VERSION ""

NS_ :

BS_:

BU_: VCM INVmc EShift HVAC TCU OBCpd HVBAT

BO_ 3221225472 VECTOR__INDEPENDENT_SIG_MSG: 0 Vector__XXX
 SG_ Unknown_55B_5 m3 : 40|8@1+ (1,0) [0|0] "" Vector__XXX
 SG_ StopChargeMaybe : 52|4@1+ (1,0) [0|0] "" Vector__XXX

BO_ 1468 x5BC: 8 HVBAT
 SG_ GIDs : 7|10@0+ (1,0) [0|500] "gids" Vector__XXX
 SG_ Mux M : 32|4@1+ (1,0) [0|0] "" Vector__XXX
 SG_ BatteryTemperature : 24|8@1+ (1,0) [0|0] "dC" Vector__XXX
 SG_ BatteryChargeGaugeOffset : 36|4@1+ (1,0) [0|15] "" Vector__XXX
 SG_ ChargeBars m8 : 20|4@1+ (1,0) [0|15] "-" Vector__XXX
 SG_ CapacityBars m9 : 20|4@1+ (1,0) [0|15] "" Vector__XXX

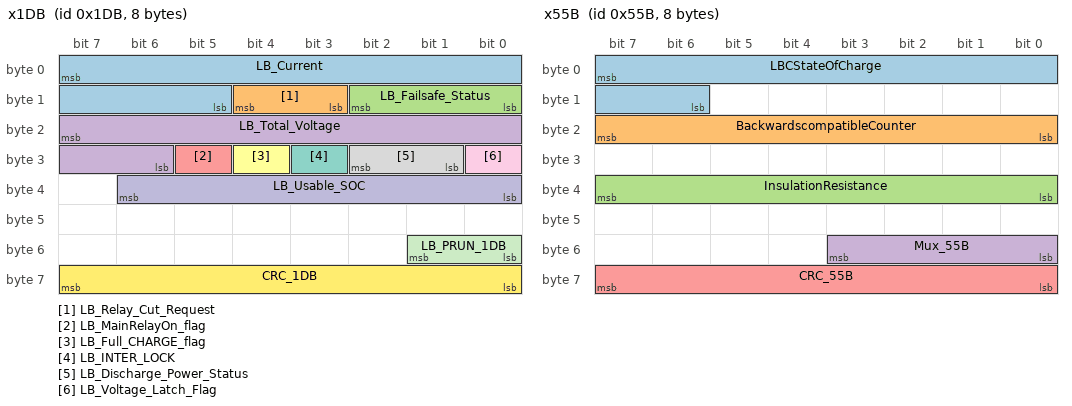
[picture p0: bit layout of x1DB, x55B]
BO_ 475 x1DB: 8 HVBAT
 SG_ LB_Current : 7|11@0+ (0.5,0) [-400|200] "A" Vector__XXX
 SG_ LB_Relay_Cut_Request : 11|2@1+ (1,0) [0|0] "MODEMASK" Vector__XXX
 SG_ LB_Failsafe_Status : 8|3@1+ (1,0) [0|0] "MODEMASK" Vector__XXX
 SG_ LB_Total_Voltage : 23|10@0+ (0.5,0) [0|450] "V" Vector__XXX
 SG_ LB_MainRelayOn_flag : 29|1@1+ (1,0) [0|0] "MODEMASK" Vector__XXX
 SG_ LB_Full_CHARGE_flag : 28|1@1+ (1,0) [0|0] "" Vector__XXX
 SG_ LB_INTER_LOCK : 27|1@1+ (1,0) [0|0] "MODEMASK" Vector__XXX
 SG_ LB_Discharge_Power_Status : 25|2@1+ (1,0) [0|0] "MODEMASK" Vector__XXX
 SG_ LB_Voltage_Latch_Flag : 24|1@1+ (1,0) [0|0] "MODEMASK" Vector__XXX
 SG_ LB_Usable_SOC : 32|7@1+ (1,0) [0|0] "" Vector__XXX
 SG_ LB_PRUN_1DB : 48|2@1+ (1,0) [0|0] "" Vector__XXX
 SG_ CRC_1DB : 56|8@1+ (1,0) [0|0] "CRC" Vector__XXX

BO_ 1371 x55B: 8 HVBAT
 SG_ LBCStateOfCharge : 7|10@0+ (1,0) [0|0] "%+1" Vector__XXX
 SG_ BackwardscompatibleCounter : 16|8@1+ (1,0) [85|170] "" Vector__XXX
 SG_ InsulationResistance : 32|8@1+ (1,0) [0|255] "" Vector__XXX
 SG_ Mux_55B M : 48|4@1+ (1,0) [0|0] "" Vector__XXX
 SG_ CRC_55B : 56|8@1+ (1,0) [0|0] "" Vector__XXX

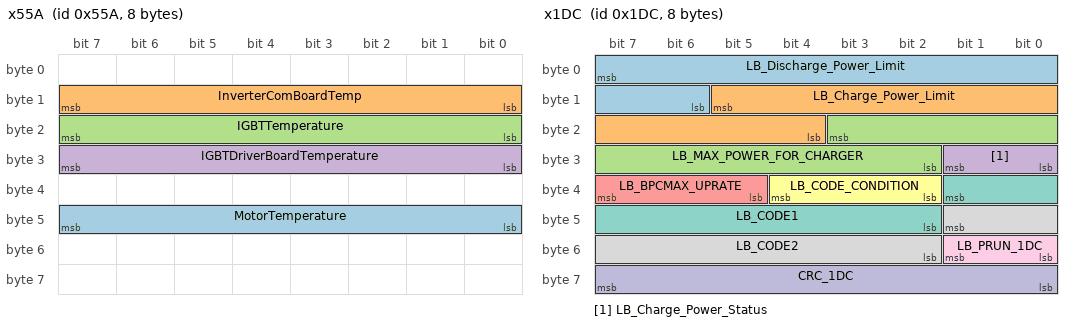
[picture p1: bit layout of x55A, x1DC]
BO_ 1370 x55A: 8 INVmc
 SG_ MotorTemperature : 40|8@1+ (1,0) [0|255] "dC*2" Vector__XXX
 SG_ InverterComBoardTemp : 8|8@1+ (1,0) [0|255] "dC*2" Vector__XXX
 SG_ IGBTTemperature : 16|8@1+ (1,0) [0|255] "dC*2" Vector__XXX
 SG_ IGBTDriverBoardTemperature : 24|8@1+ (1,0) [0|255] "dC*2" Vector__XXX

BO_ 476 x1DC: 8 HVBAT
 SG_ LB_Discharge_Power_Limit : 7|10@0+ (0.25,0) [0|254] "kW" Vector__XXX
 SG_ LB_Charge_Power_Limit : 13|10@0+ (0.25,0) [0|254] "kW" Vector__XXX
 SG_ LB_MAX_POWER_FOR_CHARGER : 19|10@0+ (0.1,-10) [-10|90] "kW" Vector__XXX
 SG_ LB_Charge_Power_Status : 24|2@1+ (1,0) [0|0] "MODEMASK" Vector__XXX
 SG_ LB_BPCMAX_UPRATE : 37|3@1+ (1,0) [0|0] "MODEMASK" Vector__XXX
 SG_ LB_CODE_CONDITION : 34|3@1+ (1,0) [0|0] "" Vector__XXX
 SG_ LB_CODE1 : 33|8@0+ (1,0) [0|0] "" Vector__XXX
 SG_ LB_CODE2 : 41|8@0+ (1,0) [0|0] "" Vector__XXX
 SG_ LB_PRUN_1DC : 48|2@1+ (1,0) [0|3] "" Vector__XXX
 SG_ CRC_1DC : 56|8@1+ (1,0) [0|0] "CRC" Vector__XXX

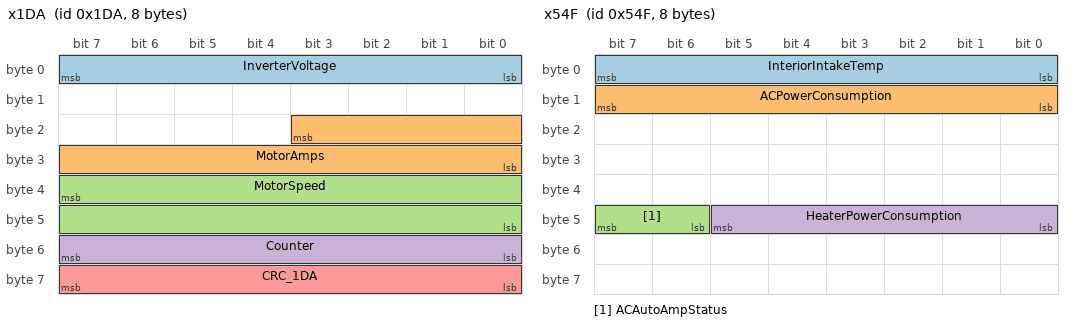
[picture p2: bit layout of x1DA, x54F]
BO_ 474 x1DA: 8 INVmc
 SG_ InverterVoltage : 0|8@1+ (1,0) [0|200] "V*2" Vector__XXX
 SG_ MotorAmps : 19|12@0+ (1,0) [0|250] "A" Vector__XXX
 SG_ MotorSpeed : 39|16@0+ (1,0) [0|24000] "rpm/2" Vector__XXX
 SG_ Counter : 48|8@1+ (1,0) [0|3] "" Vector__XXX
 SG_ CRC_1DA : 56|8@1+ (1,0) [0|0] "CRC" Vector__XXX

BO_ 1465 x5B9: 7 VCM
 SG_ ActiveFuelBars : 3|5@1+ (1,0) [0|12] "-" Vector__XXX
 SG_ ChargeMinutesRemaining : 2|11@0+ (1,0) [0|2047] "minutes" Vector__XXX

BO_ 1359 x54F: 8 HVAC
 SG_ InteriorIntakeTemp : 0|8@1+ (1,0) [0|0] "F or 0.5C" Vector__XXX
 SG_ ACPowerConsumption : 8|8@1+ (1,0) [0|0] "50W/bit?" Vector__XXX
 SG_ ACAutoAmpStatus : 46|2@1+ (1,0) [0|0] "-" Vector__XXX
 SG_ HeaterPowerConsumption : 40|6@1+ (1,0) [0|0] "300W/bit?" Vector__XXX

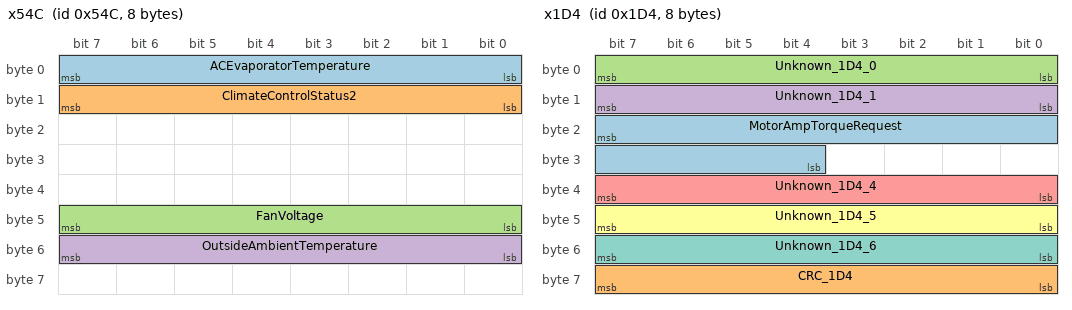
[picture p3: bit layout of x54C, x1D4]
BO_ 1356 x54C: 8 HVAC
 SG_ ACEvaporatorTemperature : 0|8@1+ (1,0) [0|0] "0.25C/bit?" Vector__XXX
 SG_ ClimateControlStatus2 : 8|8@1+ (1,0) [0|0] "-" Vector__XXX
 SG_ FanVoltage : 40|8@1+ (1,0) [0|0] "0.05 V/bit" Vector__XXX
 SG_ OutsideAmbientTemperature : 48|8@1+ (1,0) [0|0] "F/C" Vector__XXX

BO_ 282 x11A: 8 VCM
 SG_ JoystickGearPosition : 4|4@1+ (1,0) [0|0] "-" Vector__XXX
 SG_ CarOnOffStatus : 8|8@1+ (1,0) [0|0] "-" Vector__XXX
 SG_ Mulitplexor M : 48|8@1+ (1,0) [0|0] "" Vector__XXX
 SG_ StartupDataUnknown0 m0 : 56|8@1+ (1,0) [0|0] "" Vector__XXX
 SG_ StartupDataUnknown1 m1 : 56|8@1+ (1,0) [0|0] "" Vector__XXX
 SG_ StartupDataUnknown2 m2 : 56|8@1+ (1,0) [0|0] "" Vector__XXX
 SG_ StartupDataUnknown3 m3 : 56|8@1+ (1,0) [0|0] "" Vector__XXX
 SG_ SteeringWheelButton : 16|8@1+ (1,0) [0|0] "" Vector__XXX
 SG_ HeartbeatVCM : 24|8@1+ (1,0) [85|170] "" Vector__XXX
 SG_ Unknown_11A_4_0 m0 : 32|8@1+ (1,0) [0|0] "" Vector__XXX
 SG_ Unknown_11A_4_1 m1 : 32|8@1+ (1,0) [0|0] "" Vector__XXX
 SG_ Unknown_11A_4_2 m2 : 32|8@1+ (1,0) [0|0] "" Vector__XXX
 SG_ Unknown_11A_4_3 m3 : 32|8@1+ (1,0) [0|0] "" Vector__XXX

BO_ 468 x1D4: 8 Vector__XXX
 SG_ MotorAmpTorqueRequest : 23|12@0+ (1,0) [0|0] "" Vector__XXX
 SG_ CRC_1D4 : 56|8@1+ (1,0) [0|0] "CRC" Vector__XXX
 SG_ Unknown_1D4_0 : 0|8@1+ (1,0) [0|0] "" Vector__XXX
 SG_ Unknown_1D4_1 : 8|8@1+ (1,0) [0|0] "" Vector__XXX
 SG_ Unknown_1D4_4 : 32|8@1+ (1,0) [0|0] "" Vector__XXX
 SG_ Unknown_1D4_5 : 40|8@1+ (1,0) [0|0] "" Vector__XXX
 SG_ Unknown_1D4_6 : 48|8@1+ (1,0) [0|0] "" Vector__XXX

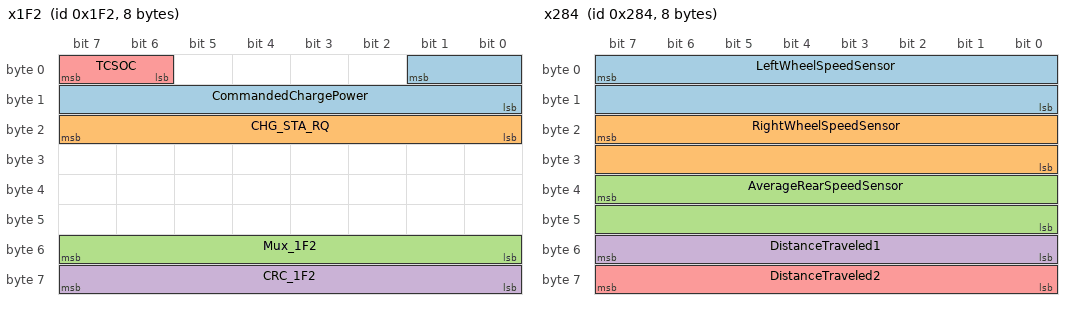
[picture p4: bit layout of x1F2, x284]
BO_ 498 x1F2: 8 VCM
 SG_ CommandedChargePower : 1|10@0+ (1,0) [0|0] "" Vector__XXX
 SG_ CHG_STA_RQ : 16|8@1+ (1,0) [0|0] "" Vector__XXX
 SG_ Mux_1F2 M : 48|8@1+ (1,0) [0|3] "" Vector__XXX
 SG_ CRC_1F2 : 56|8@1+ (1,0) [0|0] "" Vector__XXX
 SG_ TCSOC : 6|2@1+ (1,0) [0|0] "" Vector__XXX

BO_ 644 x284: 8 VCM
 SG_ LeftWheelSpeedSensor : 7|16@0+ (1,0) [0|65535] "pulses" Vector__XXX
 SG_ RightWheelSpeedSensor : 23|16@0+ (1,0) [0|65535] "pulses" Vector__XXX
 SG_ AverageRearSpeedSensor : 39|16@0+ (1,0) [0|65535] "pulses" Vector__XXX
 SG_ DistanceTraveled1 : 48|8@1+ (1,0) [0|255] "" Vector__XXX
 SG_ DistanceTraveled2 : 56|8@1+ (1,0) [0|255] "" Vector__XXX

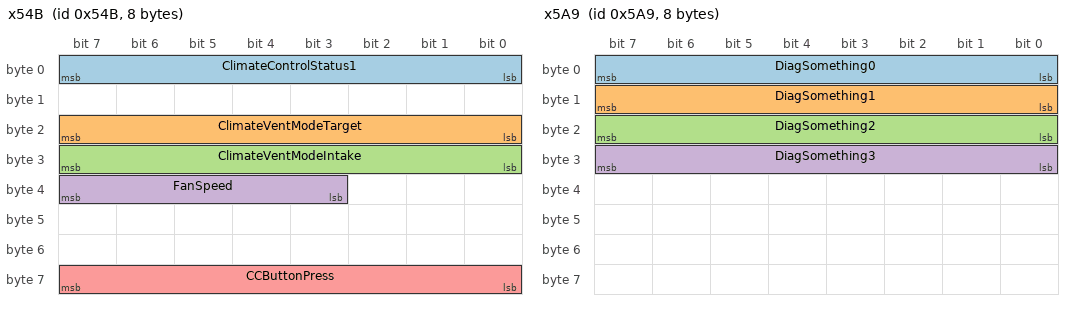
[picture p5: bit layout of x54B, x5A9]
BO_ 1355 x54B: 8 HVAC
 SG_ ClimateControlStatus1 : 0|8@1+ (1,0) [0|0] "status" Vector__XXX
 SG_ ClimateVentModeTarget : 16|8@1+ (1,0) [0|0] "status" Vector__XXX
 SG_ ClimateVentModeIntake : 24|8@1+ (1,0) [0|0] "status" Vector__XXX
 SG_ FanSpeed : 35|5@1+ (1,0) [1|7] "speed" Vector__XXX
 SG_ CCButtonPress : 56|8@1+ (1,0) [0|0] "0/1" Vector__XXX

BO_ 1449 x5A9: 8 VCM
 SG_ DiagSomething0 : 0|8@1+ (1,0) [0|0] "" Vector__XXX
 SG_ DiagSomething1 : 8|8@1+ (1,0) [0|0] "" Vector__XXX
 SG_ DiagSomething2 : 16|8@1+ (1,0) [0|0] "" Vector__XXX
 SG_ DiagSomething3 : 24|8@1+ (1,0) [0|0] "" Vector__XXX

BO_ 1472 x5C0: 8 HVBAT
 SG_ Mux5C0 M : 0|8@1+ (1,0) [0|0] "" Vector__XXX
 SG_ ClusterTemperature2 m64 : 16|8@1+ (1,0) [0|0] "dC" Vector__XXX
 SG_ DisOrChargeTimeCounter : 24|8@1- (1,0) [0|255] "Counter" Vector__XXX
 SG_ Unknown5C0_byte4 : 32|8@1+ (1,0) [0|0] "" Vector__XXX
 SG_ Unknown5C0_byte5_mux40 m64 : 40|8@1+ (1,0) [0|0] "" Vector__XXX
 SG_ Unknown5C0_byte5_mux80 m128 : 40|8@1+ (1,0) [0|0] "" Vector__XXX
 SG_ Unknown5C0_byte5_muxC0 m192 : 48|8@1+ (1,0) [0|0] "" Vector__XXX

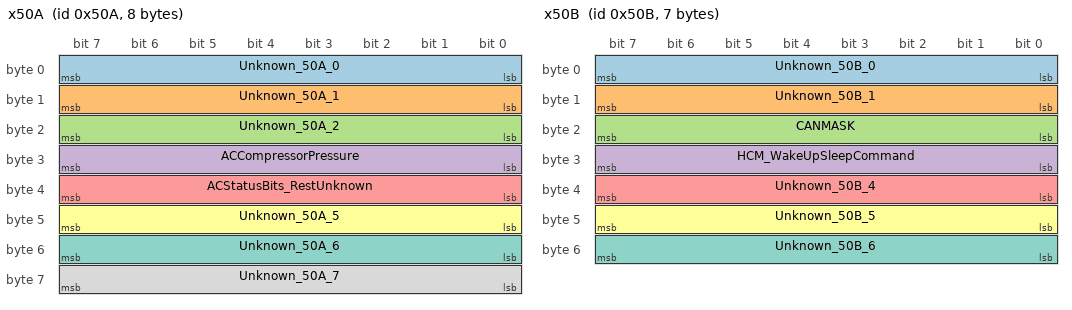
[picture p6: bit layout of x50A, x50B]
BO_ 1290 x50A: 8 VCM
 SG_ Unknown_50A_0 : 0|8@1+ (1,0) [0|0] "" Vector__XXX
 SG_ Unknown_50A_1 : 8|8@1+ (1,0) [0|0] "" Vector__XXX
 SG_ Unknown_50A_2 : 16|8@1+ (1,0) [0|0] "" Vector__XXX
 SG_ ACCompressorPressure : 24|8@1+ (1,0) [0|0] "" Vector__XXX
 SG_ ACStatusBits_RestUnknown : 32|8@1+ (1,0) [0|0] "" Vector__XXX
 SG_ Unknown_50A_5 : 40|8@1+ (1,0) [0|0] "" Vector__XXX
 SG_ Unknown_50A_6 : 48|8@1+ (1,0) [0|0] "" Vector__XXX
 SG_ Unknown_50A_7 : 56|8@1+ (1,0) [0|0] "" Vector__XXX

BO_ 1291 x50B: 7 VCM
 SG_ Unknown_50B_0 : 0|8@1+ (1,0) [0|0] "" Vector__XXX
 SG_ Unknown_50B_1 : 8|8@1+ (1,0) [0|0] "" Vector__XXX
 SG_ CANMASK : 16|8@1+ (1,0) [0|0] "" Vector__XXX
 SG_ HCM_WakeUpSleepCommand : 24|8@1+ (1,0) [0|0] "" Vector__XXX
 SG_ Unknown_50B_4 : 32|8@1+ (1,0) [0|0] "" Vector__XXX
 SG_ Unknown_50B_5 : 40|8@1+ (1,0) [0|0] "" Vector__XXX
 SG_ Unknown_50B_6 : 48|8@1+ (1,0) [0|0] "" Vector__XXX

BO_ 1292 x50C: 6 Vector__XXX
 SG_ Unknown_50C_0 : 0|8@1+ (1,0) [0|0] "" Vector__XXX
 SG_ Unknown_50C_1 : 8|8@1+ (1,0) [0|0] "" Vector__XXX
 SG_ Unknown_50C_2 : 16|8@1+ (1,0) [0|0] "" Vector__XXX
 SG_ Mux_50C M : 24|8@1+ (1,0) [0|0] "" Vector__XXX
 SG_ ALU_Question : 32|8@1+ (1,0) [0|0] "" Vector__XXX
 SG_ Unknown_50C_5_0 m0 : 40|8@1+ (1,0) [0|0] "" Vector__XXX
 SG_ Unknown_50C_5_1 m1 : 40|8@1+ (1,0) [0|0] "" Vector__XXX
 SG_ Unknown_50C_5_2 m2 : 40|8@1+ (1,0) [0|0] "" Vector__XXX
 SG_ Unknown_50C_5_3 m3 : 40|8@1+ (1,0) [0|0] "" Vector__XXX

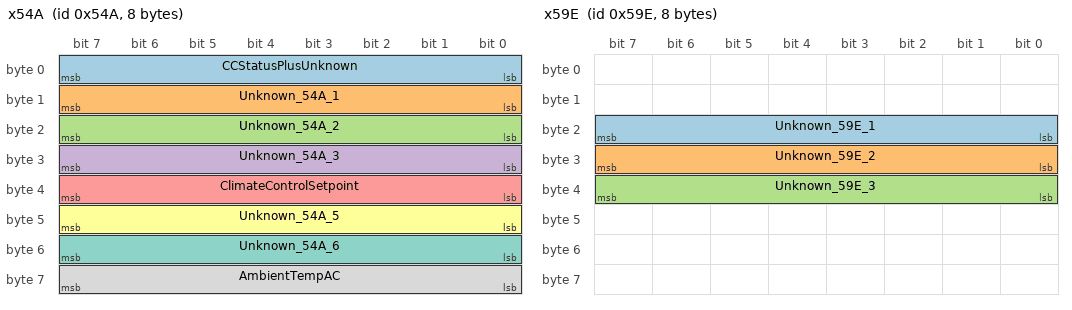
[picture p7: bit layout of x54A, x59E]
BO_ 1354 x54A: 8 HVAC
 SG_ CCStatusPlusUnknown : 0|8@1+ (1,0) [0|0] "" Vector__XXX
 SG_ Unknown_54A_1 : 8|8@1+ (1,0) [0|0] "" Vector__XXX
 SG_ Unknown_54A_2 : 16|8@1+ (1,0) [0|0] "" Vector__XXX
 SG_ Unknown_54A_3 : 24|8@1+ (1,0) [0|0] "" Vector__XXX
 SG_ ClimateControlSetpoint : 32|8@1+ (1,0) [0|0] "" Vector__XXX
 SG_ Unknown_54A_5 : 40|8@1+ (1,0) [0|0] "" Vector__XXX
 SG_ Unknown_54A_6 : 48|8@1+ (1,0) [0|0] "" Vector__XXX
 SG_ AmbientTempAC : 56|8@1+ (1,0) [0|0] "" Vector__XXX

BO_ 1118 x45E: 1 Vector__XXX

BO_ 1438 x59E: 8 Vector__XXX
 SG_ Unknown_59E_1 : 16|8@1+ (1,0) [0|0] "" Vector__XXX
 SG_ Unknown_59E_2 : 24|8@1+ (1,0) [0|0] "" Vector__XXX
 SG_ Unknown_59E_3 : 32|8@1+ (1,0) [0|0] "" Vector__XXX

BO_ 1153 x481: 2 Vector__XXX
 SG_ Unknown_481_1 : 0|8@1+ (1,0) [0|0] "" Vector__XXX
 SG_ Unknown_481_2 : 8|8@1+ (1,0) [0|0] "" Vector__XXX

BO_ 912 x390: 8 Vector__XXX
 SG_ Unknown_390_7 : 56|8@1+ (1,0) [0|0] "" Vector__XXX

BO_ 915 x393: 8 Vector__XXX
 SG_ Unknown_393_8 : 56|8@1+ (1,0) [0|0] "" Vector__XXX

BO_ 1539 x603: 8 Vector__XXX

CM_ BU_ VCM "Vehicle Control Module";
CM_ BU_ INVmc "Inverter Motor Controller";
CM_ BO_ 1468 "Lithium Battery Controller";
CM_ SG_ 1468 GIDs "0-281 for 24kWh  0-363 for 30kWh 0-498 for 40kWh
1 LSB = 65-85WH";
CM_ SG_ 1468 Mux "Mux field for capacity bars and charge bars 
8/9 on 2013-2017, 14/15 on 2018-2019";
CM_ SG_ 1468 BatteryTemperature "Should be average of the 3/4 sensors inside the battery pack (0x50 = 80DEC = 8.0*C)";
CM_ SG_ 1468 BatteryChargeGaugeOffset "Somehow effects the charge gauge, lower numbers mean more bars";
CM_ SG_ 1468 ChargeBars "Range 0-15 (Below data from test at 0%SOC, writing values to bus)
15 = 12 chargebars
14 = 12 chargebars
13 = 11 chargebars
12 = 10 chargebars
11 = 9 chargebars
10 = 8 chargebars !
9 = 8 chargebars !
8 = 7 chargebars
7 = 6 chargebars
6 = 5 chargebars
5 = 4 chargebars !
4 = 4 chargebars !
3 = 3 chargebars
2 = 2 chargebars
1 = 1 chargebars
0 = 0 chargebars";
CM_ SG_ 1468 CapacityBars "0-15 
15 = 12 capacitybars
14 = 12 capacitybars
13 = 11 capacitybars
12 = 10 capacitybars
11 = 9 capacitybars
10 = 8 capacitybars !
9 = 8 capacitybars !
8 = 7 capacitybars
7 = 6 capacitybars
6 = 5 capacitybars
5 = 4 capacitybars !
4 = 4 capacitybars !
3 = 3 capacitybars
2 = 2 capacitybars
1 = 1 capacitybars
0 = 0 capacitybars
";
CM_ BO_ 475 "Lithium Battery Controller (10ms)";
CM_ SG_ 475 LB_Current "BatteryCurrentSignal , 2s comp, 1lSB = 0.5A";
CM_ SG_ 475 LB_Relay_Cut_Request "00 = No-Request 01 = Main Relay OFF Request 10 = Main Relay OFF Request 11 = Main Relay OFF Request";
CM_ SG_ 475 LB_Failsafe_Status "Request Stop charging. This is the command to request stop charging
frame.data[1] = (frame.data[1] & 0xE0) | 2;

000b = normal start Request 001b = Normal Stop Request 010b = Charging Mode Stop Request 011b = Charging Mode Stop Request & Normal Stop Request 100b = Caution Lamp Request 101b = Caution Lamp Request & Normal Stop Request 110b = Caution Lamp Request & Charging Mode Stop Request 111b = Caution Lamp Request & Charging Mode Stop Request & Normal Stop Request";
CM_ SG_ 475 LB_Total_Voltage "0.5V/bit
";
CM_ SG_ 475 LB_MainRelayOn_flag "0h = No-Permission 1h = Main Relay On Permission";
CM_ SG_ 475 LB_INTER_LOCK "0h = Not Inter Lock connected 1h = Inter Lock connected";
CM_ SG_ 475 LB_Discharge_Power_Status "00b = Reserved 01b = Normal limit POUT 10b = High rate limit POUT 11b = Immediate limit POUT";
CM_ SG_ 475 LB_Voltage_Latch_Flag "0->1:Cell Volatage Latch
1->0:Cell Volatage Latch";
CM_ SG_ 475 LB_Usable_SOC "Contains SOC for dash (% without decimals) [Needs to be copied to this location when doing 40/62kWh swaps into AZE0]";
CM_ SG_ 475 LB_PRUN_1DB "MPR1DB";
CM_ SG_ 475 CRC_1DB "CRC";
CM_ BO_ 1371 "Lithium Battery Controller";
CM_ SG_ 1371 LBCStateOfCharge "Does not affect cluster or VCM at all";
CM_ SG_ 1371 BackwardscompatibleCounter "55,AA (alternates every 500ms) Works as a mux

This message is repeated 5x, to offer backwardscompability to 2011/2013 models. The message on these cars are run at 500ms.";
CM_ SG_ 1371 Mux_55B "00,01,02,03";
CM_ BO_ 1370 "Inverter";
CM_ SG_ 1370 MotorTemperature "Stays at 0 on 2015 Leaf?";
CM_ SG_ 1370 InverterComBoardTemp "Inverter communications board temp";
CM_ SG_ 1370 IGBTDriverBoardTemperature "Temperature only active during drive (IGBT driver board?)";
CM_ BO_ 476 "Lithium Battery Controller (10ms)";
CM_ SG_ 476 LB_Discharge_Power_Limit "Max available power that can be pulled from battery";
CM_ SG_ 476 LB_Charge_Power_Limit "Max power that battery can be charged with";
CM_ SG_ 476 LB_Charge_Power_Status "00b = Reserved 01b = Normal limit PIN 10b = High rate limit PIN 11b = Immediate limit PIN";
CM_ SG_ 476 LB_BPCMAX_UPRATE "000b : BPC MAX Uprate Level 1 001b : BPC MAX Uprate Level 2 010b : BPC MAX Uprate Level 3 011b : BPC MAX Uprate Level 4 100b : BPC MAX Uprate Level 5 101b : BPC MAX Uprate Level 6 110b : BPC MAX Uprate Level 7 111b : BPC MAX Uprate Level 8";
CM_ SG_ 476 CRC_1DC "CRC";
CM_ BO_ 474 "Inverter";
CM_ SG_ 474 InverterVoltage "2V/bit
01..b9 Follows BVS(BatteryVoltageSignal) until near end of drive (turtle?) or end of charging ";
CM_ SG_ 474 MotorAmps "Something not right here.

Motor Amps * Motor Volts is really close to pack watts*40 Maybe 1lsb=0.5A";
CM_ SG_ 474 MotorSpeed "16 bits; 1 LSB = 0.5rpm? Stays at zero when applying torque with brake on so not likely volts.";
CM_ SG_ 474 Counter "Safety counter / Or mux?";
CM_ SG_ 474 CRC_1DA "CRC";
CM_ BO_ 1465 "Vehicle Control Module";
CM_ SG_ 1465 ActiveFuelBars "From VCM->Cluster";
CM_ SG_ 1465 ChargeMinutesRemaining "Minutes from 3kW charging estimate on dash.

Example:
0x09 FE
0000 1001 1111 1110
001 1111 1110 = 510min";
CM_ BO_ 1359 "AC Auto Amp";
CM_ SG_ 1359 InteriorIntakeTemp "Appears to be interior intake temp
(2013: sometimes is <0x20 when the temp is definitely higher)

My testing during 8*C according to dash, warm interior
0x34 = 52 DEC
52F = 11C?
52/2= 26C?";
CM_ SG_ 1359 ACPowerConsumption "Rises to a steady value with ac on.  Off immediately with ac off.  No change with heater on";
CM_ SG_ 1359 ACAutoAmpStatus "location?";
CM_ SG_ 1359 HeaterPowerConsumption "Goes up slowly with heater on; no change with ac on";
CM_ BO_ 1356 "AC Auto Amp";
CM_ SG_ 1356 ACEvaporatorTemperature "drops with ac on (after short lag).  No change with heater on";
CM_ SG_ 1356 ClimateControlStatus2 "66 CC on, ff CC off";
CM_ SG_ 1356 FanVoltage "Commanded fan speed is proportional to Voltage";
CM_ SG_ 1356 OutsideAmbientTemperature "0x92=90F;0x86=79F (90F & 79F read from dash)";
CM_ BO_ 282 "Vehicle Control Module 2013+ (Shift controller module for 2011-2012)";
CM_ SG_ 282 JoystickGearPosition "(MSBits probably selected gear: 4 for D/B, 3 for N, 2 for R,0 for Parked)";
CM_ SG_ 282 Mulitplexor "0, 1, 2, 3";
CM_ SG_ 282 StartupDataUnknown0 "Activity only during startup, then holds a constant value for each channel";
CM_ SG_ 282 StartupDataUnknown1 "Activity only during startup, then holds a constant value for each channel";
CM_ SG_ 282 StartupDataUnknown2 "Activity only during startup, then holds a constant value for each channel";
CM_ SG_ 282 StartupDataUnknown3 "Activity only during startup, then holds a constant value for each channel";
CM_ SG_ 282 SteeringWheelButton "00,04,80 observed here (ECO button logic here?)";
CM_ SG_ 282 HeartbeatVCM "55,AA (alternating between these two values, heartbeat?)
01010101
10101010";
CM_ BO_ 468 "Vehicle Control Module?";
CM_ SG_ 468 MotorAmpTorqueRequest "Motor Amps?  Requested Torque?
Less noisy than the 1da signal";
CM_ SG_ 468 CRC_1D4 "CRC";
CM_ BO_ 498 "Vehicle Control Module";
CM_ SG_ 498 CommandedChargePower "? 64 drive, 84-64 charge (tapers at end)";
CM_ SG_ 498 CHG_STA_RQ "CHG_STA_RQ (1F2 byte 2 bit 6 length 2)

From muxsan document. Charging start request?";
CM_ SG_ 498 TCSOC "Position in frame?";
CM_ BO_ 644 "ABS module relayed via VCM to EV-CAN";
CM_ SG_ 644 LeftWheelSpeedSensor "2's comp";
CM_ SG_ 644 RightWheelSpeedSensor "2's comp";
CM_ SG_ 644 AverageRearSpeedSensor "??? speed sensor.  Maybe average of both rear?";
CM_ SG_ 644 DistanceTraveled1 "00..ff (wraps ~360 times in a 25 mile drive)";
CM_ SG_ 644 DistanceTraveled2 "00..ff (wraps ~360 times in a 25 mile drive)";
CM_ BO_ 1355 "AC Auto Amp";
CM_ SG_ 1355 ClimateControlStatus1 "00 CC on, 01 CC off (2013: 0x10 or 0x11)";
CM_ SG_ 1355 ClimateVentModeTarget "(face/feet/defrost)";
CM_ SG_ 1355 ClimateVentModeIntake "(recirculating/fresh air/defrost)";
CM_ SG_ 1355 FanSpeed "1<->7 ";
CM_ SG_ 1355 CCButtonPress "Alternates after every CC button press, probably to alert A/V to display CC info";
CM_ BO_ 1449 "Vehicle Control Module

This message appeared after recall/update in March 2012. Probably VCM to TCU for carwings (engineering data)";
CM_ SG_ 1449 DiagSomething0 "Active during drive, FF charge";
CM_ SG_ 1449 DiagSomething1 "Active during drive, FF charge";
CM_ SG_ 1449 DiagSomething3 "Seems to be related to SOC but not LTI";
CM_ BO_ 1472 "Lithium Battery Controller";
CM_ SG_ 1472 Mux5C0 "40,80,c0";
CM_ SG_ 1472 ClusterTemperature2 "Position in the frame? The indicated temperature on the instrument cluster is controlled by another muxed field, when 0x5C0 is 0x40, the indicated temperature is controlled by the 3rd byte of 0x5C0

Dala: Doesn't seem to line up, third byte 0x60 = 6 when on the cluster 4 temp bars are active.";
CM_ SG_ 1472 DisOrChargeTimeCounter "Linear positive ramp up during charge and negative ramp down during discharge.  Starts from 00 regardless of initial charge level. Charging time?";
CM_ SG_ 1472 Unknown5C0_byte4 "a4 for TT, I have 7C here (2015 S C5/C9 depending on mux)";
CM_ SG_ 1472 Unknown5C0_byte5_mux40 "UnknownValue lies here. Multiplexed field";
CM_ SG_ 1472 Unknown5C0_byte5_mux80 "UnknownValue lies here. Multiplexed field";
CM_ SG_ 1472 Unknown5C0_byte5_muxC0 "UnknownValue lies here. Multiplexed field";
CM_ BO_ 1290 "VCM relay from A/C Auto Amp and AC Pressor Sensor (which is measured directly from VCM) Message is identical on EV CAN and CAR CAN";
CM_ SG_ 1290 Unknown_50A_0 "04,84,85";
CM_ SG_ 1290 Unknown_50A_1 "02,13,33,40,42,53,72,73 Dala (ECO button affects?)";
CM_ SG_ 1290 Unknown_50A_2 "00,a0";
CM_ SG_ 1290 ACCompressorPressure "Some sort of pressure/temperature?? 2c-44;

rises with AC on; slow decay when off";
CM_ SG_ 1290 ACStatusBits_RestUnknown "00,80  BIT1 = Rear defrost on/off";
CM_ SG_ 1290 Unknown_50A_5 "a0";
CM_ SG_ 1290 Unknown_50A_6 "04 , Only present in 2013+ (otherwise frame stops at 6bytes)";
CM_ SG_ 1290 Unknown_50A_7 "00 , Only present in 2013+ (otherwise frame stops at 6bytes)";
CM_ BO_ 1291 "HCM_WakeUpSleepCommand";
CM_ SG_ 1291 Unknown_50B_0 "00";
CM_ SG_ 1291 Unknown_50B_1 "00";
CM_ SG_ 1291 CANMASK "00,02,06 (for 2013+: also 0x04)

Bootup sequence: 06,00,02,06";
CM_ SG_ 1291 HCM_WakeUpSleepCommand "C0 from log";
CM_ SG_ 1291 Unknown_50B_4 "00";
CM_ SG_ 1291 Unknown_50B_5 "00,60 (for 2013: 0x00 only)";
CM_ SG_ 1291 Unknown_50B_6 "00, Only present in 2013+ (otherwise frame stops at 6bytes)";
CM_ BO_ 1292 "??? Unknown sender module";
CM_ SG_ 1292 Unknown_50C_0 "00";
CM_ SG_ 1292 Unknown_50C_1 "00";
CM_ SG_ 1292 Unknown_50C_2 "00 (for 2013+ also 06)";
CM_ SG_ 1292 Mux_50C "0,1,2,3";
CM_ SG_ 1292 ALU_Question "5d,b2 Dala: Used for backwardscompability?";
CM_ SG_ 1292 Unknown_50C_5_0 "Dala, def muxed

Mux 1 and 2 look like the inverse of 0 and 3";
CM_ SG_ 1292 Unknown_50C_5_1 "Dala, def muxed";
CM_ SG_ 1292 Unknown_50C_5_2 "Dala, def muxed";
CM_ SG_ 1292 Unknown_50C_5_3 "Dala, def muxed";
CM_ BO_ 1354 "AC Auto Amp";
CM_ SG_ 1354 CCStatusPlusUnknown "12,3c- CC Off; a0,da- CC On";
CM_ SG_ 1354 Unknown_54A_1 "00 (80 in 2013+)";
CM_ SG_ 1354 Unknown_54A_2 "70";
CM_ SG_ 1354 Unknown_54A_3 "06,0a,0b,0f";
CM_ SG_ 1354 ClimateControlSetpoint "00,39,52,53,54 (MY2011,2012)";
CM_ SG_ 1354 Unknown_54A_5 "00";
CM_ SG_ 1354 Unknown_54A_6 "00";
CM_ SG_ 1354 AmbientTempAC "Appears to track ambient (+41)
4f,8c-90";
CM_ BO_ 1118 "??? Unknown sender module(Also empty)";
CM_ BO_ 1438 "??? Unknown sender module";
CM_ SG_ 1438 Unknown_59E_1 "0e always? Rest of the signals in this message are empty";
CM_ SG_ 1438 Unknown_59E_2 "60 always?";
CM_ SG_ 1438 Unknown_59E_3 "Dala: DEC 152, 144, 136 seen here in short log";
CM_ BO_ 1153 "??? Unknown sender module";
CM_ SG_ 1153 Unknown_481_1 "Dala: Static 0x40";
CM_ SG_ 1153 Unknown_481_2 "Dala: Static 0x00";
CM_ BO_ 912 "??? Unknown sender module";
CM_ SG_ 912 Unknown_390_7 "Sawtooth, from 200-250";
CM_ BO_ 915 "??? Unknown sender module";
CM_ SG_ 915 Unknown_393_8 "Sawtooth between 03,14,36";
CM_ BO_ 1539 "Bootup Message, appears once during power on after a few sec";
VAL_ 1468 Mux 8 "Fuel bars" 9 "Capacity bars" ;
VAL_ 475 LB_Relay_Cut_Request 0 "No-Request" 1 "Main Relay OFF Request" 2 "Main Relay OFF Request" 3 "Main Relay OFF Request" ;
VAL_ 475 LB_Failsafe_Status 0 "Normal Start Request" 1 "Normal Stop Request" 2 "Charging Mode Stop Request" 3 "Charging Mode Stop Request & Normal Stop Request" 4 "Caution Lamp Request" 5 "Caution Lamp Request & Normal Stop Request" 6 "Caution Lamp Request & Charging Mode Stop Request" 7 "Caution Lamp Request & Charging Mode Stop Request & Normal Stop Request" ;
VAL_ 475 LB_MainRelayOn_flag 0 "No-Permission" 1 "Main Relay On Permission" ;
VAL_ 475 LB_INTER_LOCK 0 "Not Inter Lock connected" 1 "Inter Lock connected" ;
VAL_ 475 LB_Discharge_Power_Status 0 "Reserved" 1 "Normal limit POUT" 2 "High rate limit POUT" 3 " Immediate limit POUT" ;
VAL_ 476 LB_Charge_Power_Status 0 "Reserved" 1 "Normal limit PIN" 2 "High rate limit PIN" 3 "Immediate limit PIN" ;
VAL_ 476 LB_BPCMAX_UPRATE 0 "BPC MAX Uprate Level 1" 1 "BPC MAX Uprate Level 2" 2 "BPC MAX Uprate Level 3" 3 "BPC MAX Uprate Level 4" 4 "BPC MAX Uprate Level 5" 5 "BPC MAX Uprate Level 6" 6 "BPC MAX Uprate Level 7" 7 "BPC MAX Uprate Level 8" ;
VAL_ 1356 ClimateControlStatus2 102 "CC ON" 255 "CC OFF" ;
VAL_ 282 JoystickGearPosition 2 "Reverse" 3 "Neutral" 4 "Drive/B" 0 "Parked" ;
VAL_ 282 CarOnOffStatus 64 "CarOff" 128 "CarOn" ;
VAL_ 498 CommandedChargePower 64 "Drive" ;
VAL_ 1355 ClimateControlStatus1 16 "CC On" 17 "CC Off" 0 "CC On" 1 "CC Off" ;
VAL_ 1355 ClimateVentModeTarget 128 "CC OFF" 136 "Face only" 144 "Face/Feet" 152 "Feet only" 160 "Feet/Defrost" 168 "Defrost only" ;
VAL_ 1355 ClimateVentModeIntake 9 "Recirculate" 18 "Fresh air" 146 "Defrost" ;
VAL_ 1449 DiagSomething0 255 "Charging" ;
VAL_ 1449 DiagSomething1 255 "Charging" ;
VAL_ 1472 Mux5C0 64 "TemperatureActive" 128 "UnknownMux" 192 "UnknownMux2" ;
